# RL6955_IP_SVD register map
Vendor: Realtek
Registers are 32-bit, read-write, reset 0x0 unless marked. A register's access mark holds for its fields unless they carry their own. Offsets are from the block's base; [hi:lo] are bit positions; {n}, {i} and the like mark numbered series; <NAME> marks a mode.

## MGEN_ON
Base 0x40000000
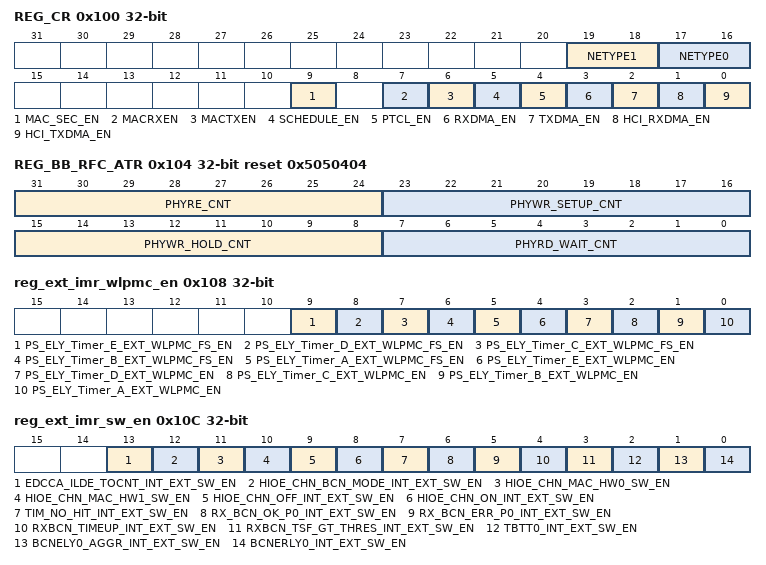
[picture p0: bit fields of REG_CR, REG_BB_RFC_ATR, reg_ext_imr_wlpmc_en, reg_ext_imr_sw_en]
0x100 REG_CR — MAC TOP Function enable
  [19:18] NETYPE1 — Network Type for Port 1 00: No link 01: Link in ad hoc network 10: Link in infrastructure network 11:AP mode Default:00b.
  [17:16] NETYPE0 — Network Type for port 0 00: No link 01: Link in ad hoc network 10: Link in infrastructure network 11:AP mode Default:00b.
  [9] MAC_SEC_EN — Enable MAC security engine When this bit is clear, security engine is reset
  [7] MACRXEN — MAC Receiver Enable. When set to 1, and the receive state machine is idle, the receive machine becomes active. This bit will read back as 1 whenever the receive state machine is active. After initial power-up, software must ensure that the receiver has completely reset before setting this bit. 1: Enable 0: Disable Default: 0b.
  [6] MACTXEN — MAC Transmitter Enable. When set to 1, and the transmit state machine is idle, the transmit state machine becomes active. This bit will read back as 1 whenever the transmit state machine is active. After initial power-up, software must ensure that the transmitter has completely reset before setting this bit. 1: Enable 0: Disable Default: 0b.
  [5] SCHEDULE_EN — Schedule Enable.
  [4] PTCL_EN — protocol Block Function Enable.(FW2HW)
  [3] RXDMA_EN — RXDMA Function Enable
  [2] TXDMA_EN — TXDMA Function Enable
  [1] HCI_RXDMA_EN — HCI to RXDMA Interface Enable
  [0] HCI_TXDMA_EN — HCI to TXDMA Interface Enable
0x104 REG_BB_RFC_ATR reset 0x5050404 — BB/RFC REG Access Time Register
  [31:24] PHYRE_CNT
  [23:16] PHYWR_SETUP_CNT — the timing WDATA stable before WE for host/cpu access BB/RFC REG
  [15:8] PHYWR_HOLD_CNT — the timing WDATA stable after WE for host/cpu access BB/RFC REG
  [7:0] PHYRD_WAIT_CNT — the timing RDATA stable after ADDR for host/cpu access BB/RFC REG
0x108 reg_ext_imr_wlpmc_en
  [9] PS_ELY_Timer_E_EXT_WLPMC_FS_EN, [8] PS_ELY_Timer_D_EXT_WLPMC_FS_EN, [7] PS_ELY_Timer_C_EXT_WLPMC_FS_EN, [6] PS_ELY_Timer_B_EXT_WLPMC_FS_EN, [5] PS_ELY_Timer_A_EXT_WLPMC_FS_EN, [4] PS_ELY_Timer_E_EXT_WLPMC_EN, [3] PS_ELY_Timer_D_EXT_WLPMC_EN, [2] PS_ELY_Timer_C_EXT_WLPMC_EN, [1] PS_ELY_Timer_B_EXT_WLPMC_EN, [0] PS_ELY_Timer_A_EXT_WLPMC_EN
0x10C reg_ext_imr_sw_en
  [13] EDCCA_ILDE_TOCNT_INT_EXT_SW_EN — when edcca is low after tbtt, start timer,when timeout for few times,set this interrupt
  [12] HIOE_CHN_BCN_MODE_INT_EXT_SW_EN — hioe_chn_bcn_mode done interrupt
  [11] HIOE_CHN_MAC_HW0_SW_EN — hioe_chn_mac_hw0 done interrupt
  [10] HIOE_CHN_MAC_HW1_SW_EN — hioe_chn_mac_hw1 done interrupt
  [9] HIOE_CHN_OFF_INT_EXT_SW_EN — hioe_chn_off done interrupt
  [8] HIOE_CHN_ON_INT_EXT_SW_EN — hioe_chn_on done interrupt
  [7] TIM_NO_HIT_INT_EXT_SW_EN — when no my aid or aid is 0(0x16DC[8]) or my bssid is not in tim element(0x16DB[31]),generate this interrupt
  [6] RX_BCN_OK_P0_INT_EXT_SW_EN — When this bit is enable, the interrupt is issued when RX beacon frame occurs in port0.
  [5] RX_BCN_ERR_P0_INT_EXT_SW_EN — When this bit is enable, the interrupt is issued when RX beacon frame with fcs error occurs in port0.
  [4] RXBCN_TIMEUP_INT_EXT_SW_EN — When this bit is enable, the interrupt is issued when RX beacon frame timeout occurs in port0.
  [3] RXBCN_TSF_GT_THRES_INT_EXT_SW_EN — The interrupt is issued when difference of tsft in beacon frame of port0 is greater than threshold
  [2] TBTT0_INT_EXT_SW_EN — the interrupt from the exact TBTT time for P0 MBSSID0.
  [1] BCNELY0_AGGR_INT_EXT_SW_EN — port 0 Beacon early aggregation interrupt
  [0] BCNERLY0_INT_EXT_SW_EN — This interrupt is issued at the time set by DRVERLYINT register before TBTT0_MB0 time.
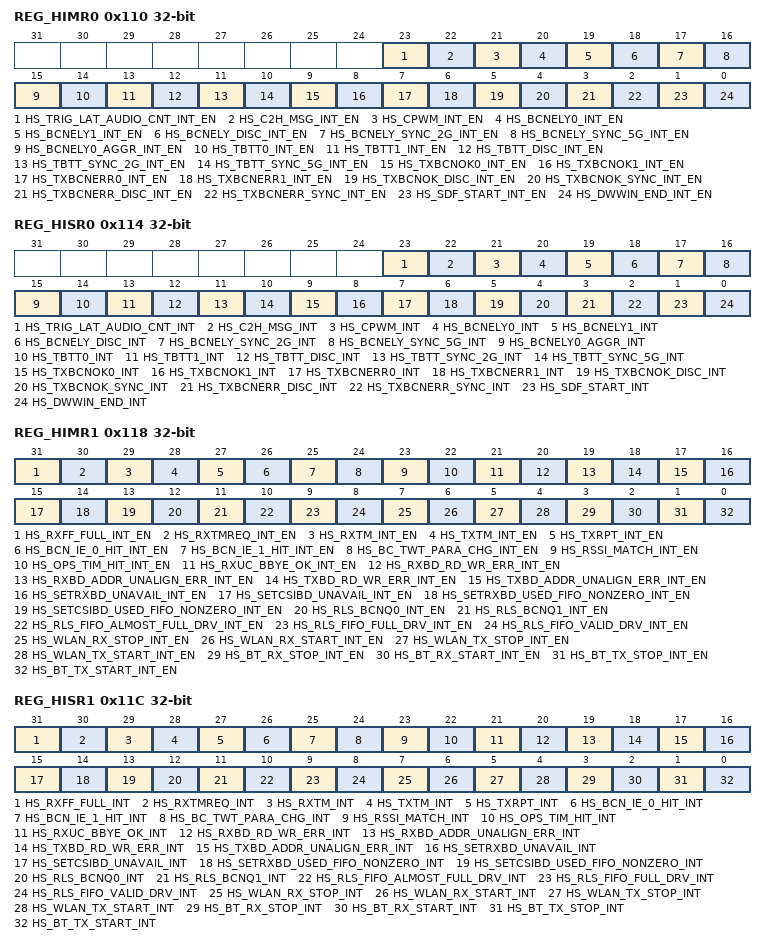
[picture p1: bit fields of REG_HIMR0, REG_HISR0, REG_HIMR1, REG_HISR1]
0x110 REG_HIMR0
  [23] HS_TRIG_LAT_AUDIO_CNT_INT_EN, [22] HS_C2H_MSG_INT_EN, [21] HS_CPWM_INT_EN, [20] HS_BCNELY0_INT_EN, [19] HS_BCNELY1_INT_EN, [18] HS_BCNELY_DISC_INT_EN, [17] HS_BCNELY_SYNC_2G_INT_EN, [16] HS_BCNELY_SYNC_5G_INT_EN, [15] HS_BCNELY0_AGGR_INT_EN, [14] HS_TBTT0_INT_EN, [13] HS_TBTT1_INT_EN, [12] HS_TBTT_DISC_INT_EN, [11] HS_TBTT_SYNC_2G_INT_EN, [10] HS_TBTT_SYNC_5G_INT_EN, [9] HS_TXBCNOK0_INT_EN, [8] HS_TXBCNOK1_INT_EN, [7] HS_TXBCNERR0_INT_EN, [6] HS_TXBCNERR1_INT_EN, [5] HS_TXBCNOK_DISC_INT_EN, [4] HS_TXBCNOK_SYNC_INT_EN, [3] HS_TXBCNERR_DISC_INT_EN, [2] HS_TXBCNERR_SYNC_INT_EN, [1] HS_SDF_START_INT_EN, [0] HS_DWWIN_END_INT_EN
0x114 REG_HISR0 ro
  [23] HS_TRIG_LAT_AUDIO_CNT_INT, [22] HS_C2H_MSG_INT, [21] HS_CPWM_INT, [20] HS_BCNELY0_INT, [19] HS_BCNELY1_INT, [18] HS_BCNELY_DISC_INT, [17] HS_BCNELY_SYNC_2G_INT, [16] HS_BCNELY_SYNC_5G_INT, [15] HS_BCNELY0_AGGR_INT, [14] HS_TBTT0_INT, [13] HS_TBTT1_INT, [12] HS_TBTT_DISC_INT, [11] HS_TBTT_SYNC_2G_INT, [10] HS_TBTT_SYNC_5G_INT, [9] HS_TXBCNOK0_INT, [8] HS_TXBCNOK1_INT, [7] HS_TXBCNERR0_INT, [6] HS_TXBCNERR1_INT, [5] HS_TXBCNOK_DISC_INT, [4] HS_TXBCNOK_SYNC_INT, [3] HS_TXBCNERR_DISC_INT, [2] HS_TXBCNERR_SYNC_INT, [1] HS_SDF_START_INT, [0] HS_DWWIN_END_INT
0x118 REG_HIMR1
  [31] HS_RXFF_FULL_INT_EN, [30] HS_RXTMREQ_INT_EN, [29] HS_RXTM_INT_EN, [28] HS_TXTM_INT_EN, [27] HS_TXRPT_INT_EN, [26] HS_BCN_IE_0_HIT_INT_EN, [25] HS_BCN_IE_1_HIT_INT_EN, [24] HS_BC_TWT_PARA_CHG_INT_EN, [23] HS_RSSI_MATCH_INT_EN, [22] HS_OPS_TIM_HIT_INT_EN, [21] HS_RXUC_BBYE_OK_INT_EN, [20] HS_RXBD_RD_WR_ERR_INT_EN, [19] HS_RXBD_ADDR_UNALIGN_ERR_INT_EN, [18] HS_TXBD_RD_WR_ERR_INT_EN, [17] HS_TXBD_ADDR_UNALIGN_ERR_INT_EN, [16] HS_SETRXBD_UNAVAIL_INT_EN, [15] HS_SETCSIBD_UNAVAIL_INT_EN, [14] HS_SETRXBD_USED_FIFO_NONZERO_INT_EN, [13] HS_SETCSIBD_USED_FIFO_NONZERO_INT_EN, [12] HS_RLS_BCNQ0_INT_EN, [11] HS_RLS_BCNQ1_INT_EN, [10] HS_RLS_FIFO_ALMOST_FULL_DRV_INT_EN, [9] HS_RLS_FIFO_FULL_DRV_INT_EN, [8] HS_RLS_FIFO_VALID_DRV_INT_EN, [7] HS_WLAN_RX_STOP_INT_EN, [6] HS_WLAN_RX_START_INT_EN, [5] HS_WLAN_TX_STOP_INT_EN, [4] HS_WLAN_TX_START_INT_EN, [3] HS_BT_RX_STOP_INT_EN, [2] HS_BT_RX_START_INT_EN, [1] HS_BT_TX_STOP_INT_EN, [0] HS_BT_TX_START_INT_EN
0x11C REG_HISR1 ro
  [31] HS_RXFF_FULL_INT, [30] HS_RXTMREQ_INT, [29] HS_RXTM_INT, [28] HS_TXTM_INT, [27] HS_TXRPT_INT, [26] HS_BCN_IE_0_HIT_INT, [25] HS_BCN_IE_1_HIT_INT, [24] HS_BC_TWT_PARA_CHG_INT, [23] HS_RSSI_MATCH_INT, [22] HS_OPS_TIM_HIT_INT, [21] HS_RXUC_BBYE_OK_INT, [20] HS_RXBD_RD_WR_ERR_INT, [19] HS_RXBD_ADDR_UNALIGN_ERR_INT, [18] HS_TXBD_RD_WR_ERR_INT, [17] HS_TXBD_ADDR_UNALIGN_ERR_INT, [16] HS_SETRXBD_UNAVAIL_INT, [15] HS_SETCSIBD_UNAVAIL_INT, [14] HS_SETRXBD_USED_FIFO_NONZERO_INT, [13] HS_SETCSIBD_USED_FIFO_NONZERO_INT, [12] HS_RLS_BCNQ0_INT, [11] HS_RLS_BCNQ1_INT, [10] HS_RLS_FIFO_ALMOST_FULL_DRV_INT, [9] HS_RLS_FIFO_FULL_DRV_INT, [8] HS_RLS_FIFO_VALID_DRV_INT, [7] HS_WLAN_RX_STOP_INT, [6] HS_WLAN_RX_START_INT, [5] HS_WLAN_TX_STOP_INT, [4] HS_WLAN_TX_START_INT, [3] HS_BT_RX_STOP_INT, [2] HS_BT_RX_START_INT, [1] HS_BT_TX_STOP_INT, [0] HS_BT_TX_START_INT
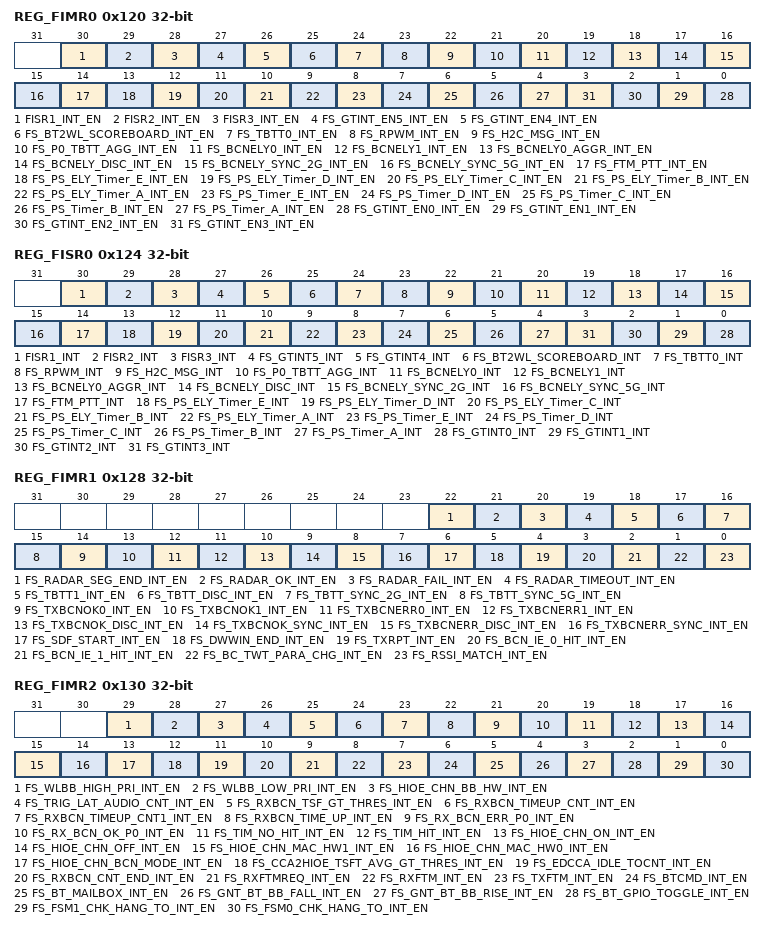
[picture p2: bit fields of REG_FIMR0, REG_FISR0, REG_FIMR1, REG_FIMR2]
0x120 REG_FIMR0
  [30] FISR1_INT_EN — FISR1 Indicator
  [29] FISR2_INT_EN — FISR2 Indicator
  [28] FISR3_INT_EN — FISR3 Indicator
  [27] FS_GTINT_EN5_INT_EN — General Timer[5] interrupt
  [26] FS_GTINT_EN4_INT_EN — General Timer[4] interrupt
  [25] FS_BT2WL_SCOREBOARD_INT_EN
  [24] FS_TBTT0_INT_EN
  [23] FS_RPWM_INT_EN
  [22] FS_H2C_MSG_INT_EN
  [21] FS_P0_TBTT_AGG_INT_EN — the interrupt from the multiplt TBTT times for P0.
  [20] FS_BCNELY0_INT_EN
  [19] FS_BCNELY1_INT_EN
  [18] FS_BCNELY0_AGGR_INT_EN
  [17] FS_BCNELY_DISC_INT_EN
  [16] FS_BCNELY_SYNC_2G_INT_EN
  [15] FS_BCNELY_SYNC_5G_INT_EN
  [14] FS_FTM_PTT_INT_EN
  [13] FS_PS_ELY_Timer_E_INT_EN
  [12] FS_PS_ELY_Timer_D_INT_EN
  [11] FS_PS_ELY_Timer_C_INT_EN
  [10] FS_PS_ELY_Timer_B_INT_EN
  [9] FS_PS_ELY_Timer_A_INT_EN
  [8] FS_PS_Timer_E_INT_EN
  [7] FS_PS_Timer_D_INT_EN
  [6] FS_PS_Timer_C_INT_EN
  [5] FS_PS_Timer_B_INT_EN
  [4] FS_PS_Timer_A_INT_EN
  [n] FS_GTINT_EN{n}_INT_EN (n=0..3) — General Timer[{n}] interrupt
0x124 REG_FISR0 ro
  [30] FISR1_INT — FISR1 Indicator
  [29] FISR2_INT — FISR2 Indicator
  [28] FISR3_INT — FISR3 Indicator
  [27] FS_GTINT5_INT — General Timer[5] interrupt
  [26] FS_GTINT4_INT — General Timer[4] interrupt
  [25] FS_BT2WL_SCOREBOARD_INT
  [24] FS_TBTT0_INT
  [23] FS_RPWM_INT
  [22] FS_H2C_MSG_INT
  [21] FS_P0_TBTT_AGG_INT — the interrupt from the multiplt TBTT times for P0.
  [20] FS_BCNELY0_INT
  [19] FS_BCNELY1_INT
  [18] FS_BCNELY0_AGGR_INT
  [17] FS_BCNELY_DISC_INT
  [16] FS_BCNELY_SYNC_2G_INT
  [15] FS_BCNELY_SYNC_5G_INT
  [14] FS_FTM_PTT_INT
  [13] FS_PS_ELY_Timer_E_INT
  [12] FS_PS_ELY_Timer_D_INT
  [11] FS_PS_ELY_Timer_C_INT
  [10] FS_PS_ELY_Timer_B_INT
  [9] FS_PS_ELY_Timer_A_INT
  [8] FS_PS_Timer_E_INT
  [7] FS_PS_Timer_D_INT
  [6] FS_PS_Timer_C_INT
  [5] FS_PS_Timer_B_INT
  [4] FS_PS_Timer_A_INT
  [n] FS_GTINT{n}_INT (n=0..3) — General Timer[{n}] interrupt
0x128 REG_FIMR1
  [22] FS_RADAR_SEG_END_INT_EN, [21] FS_RADAR_OK_INT_EN, [20] FS_RADAR_FAIL_INT_EN, [19] FS_RADAR_TIMEOUT_INT_EN, [18] FS_TBTT1_INT_EN, [17] FS_TBTT_DISC_INT_EN, [16] FS_TBTT_SYNC_2G_INT_EN, [15] FS_TBTT_SYNC_5G_INT_EN, [14] FS_TXBCNOK0_INT_EN, [13] FS_TXBCNOK1_INT_EN, [12] FS_TXBCNERR0_INT_EN, [11] FS_TXBCNERR1_INT_EN, [10] FS_TXBCNOK_DISC_INT_EN, [9] FS_TXBCNOK_SYNC_INT_EN, [8] FS_TXBCNERR_DISC_INT_EN, [7] FS_TXBCNERR_SYNC_INT_EN, [6] FS_SDF_START_INT_EN, [5] FS_DWWIN_END_INT_EN, [4] FS_TXRPT_INT_EN, [3] FS_BCN_IE_0_HIT_INT_EN, [2] FS_BCN_IE_1_HIT_INT_EN, [1] FS_BC_TWT_PARA_CHG_INT_EN, [0] FS_RSSI_MATCH_INT_EN
0x130 REG_FIMR2
  [29] FS_WLBB_HIGH_PRI_INT_EN, [28] FS_WLBB_LOW_PRI_INT_EN, [27] FS_HIOE_CHN_BB_HW_INT_EN, [26] FS_TRIG_LAT_AUDIO_CNT_INT_EN, [25] FS_RXBCN_TSF_GT_THRES_INT_EN, [24] FS_RXBCN_TIMEUP_CNT_INT_EN, [23] FS_RXBCN_TIMEUP_CNT1_INT_EN, [22] FS_RXBCN_TIME_UP_INT_EN, [21] FS_RX_BCN_ERR_P0_INT_EN, [20] FS_RX_BCN_OK_P0_INT_EN, [19] FS_TIM_NO_HIT_INT_EN, [18] FS_TIM_HIT_INT_EN, [17] FS_HIOE_CHN_ON_INT_EN, [16] FS_HIOE_CHN_OFF_INT_EN, [15] FS_HIOE_CHN_MAC_HW1_INT_EN, [14] FS_HIOE_CHN_MAC_HW0_INT_EN, [13] FS_HIOE_CHN_BCN_MODE_INT_EN, [12] FS_CCA2HIOE_TSFT_AVG_GT_THRES_INT_EN, [11] FS_EDCCA_IDLE_TOCNT_INT_EN, [10] FS_RXBCN_CNT_END_INT_EN, [9] FS_RXFTMREQ_INT_EN, [8] FS_RXFTM_INT_EN, [7] FS_TXFTM_INT_EN, [6] FS_BTCMD_INT_EN, [5] FS_BT_MAILBOX_INT_EN, [4] FS_GNT_BT_BB_FALL_INT_EN, [3] FS_GNT_BT_BB_RISE_INT_EN, [2] FS_BT_GPIO_TOGGLE_INT_EN, [1] FS_FSM1_CHK_HANG_TO_INT_EN, [0] FS_FSM0_CHK_HANG_TO_INT_EN
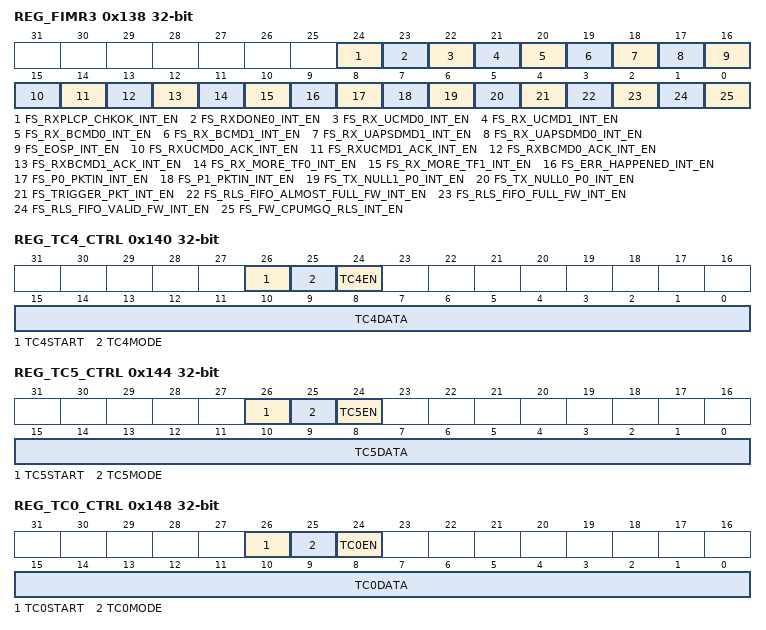
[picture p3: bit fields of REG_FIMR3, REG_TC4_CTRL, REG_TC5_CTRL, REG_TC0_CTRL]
0x138 REG_FIMR3
  [24] FS_RXPLCP_CHKOK_INT_EN — RXPCLP check ok interrupt
  [23] FS_RXDONE0_INT_EN — Rx Packet 0 done interrupt (for WOL release packet)
  [22] FS_RX_UCMD0_INT_EN — The interrupt is issued while receiving unicast data frame with More Data=0
  [21] FS_RX_UCMD1_INT_EN — The interrupt is issued while receiving unicast data frame with More Data=1
  [20] FS_RX_BCMD0_INT_EN — The interrupt is issued while receiving broadcast data frame with More Data=0
  [19] FS_RX_BCMD1_INT_EN — The interrupt is issued while receiving broadcast data frame with More Data=1
  [18] FS_RX_UAPSDMD1_INT_EN — Setting this bit indicates Rx pkt is matched with one of below: 1.) QoS Unicast data frame with MD=1, UAPSD=0 2.) NonQoS Unicast data frame with MD=1
  [17] FS_RX_UAPSDMD0_INT_EN — Setting this bit indicates Rx pkt is matched with one of below: 1.) QoS Unicast data frame with MD=0, UAPSD=0 2.) NonQoS Unicast data frame with MD=0
  [16] FS_EOSP_INT_EN — EOSP_INT interrupt mask
  [15] FS_RXUCMD0_ACK_INT_EN
  [14] FS_RXUCMD1_ACK_INT_EN
  [13] FS_RXBCMD0_ACK_INT_EN
  [12] FS_RXBCMD1_ACK_INT_EN
  [11] FS_RX_MORE_TF0_INT_EN
  [10] FS_RX_MORE_TF1_INT_EN
  [9] FS_ERR_HAPPENED_INT_EN — FWHW/ WMAC error status interrupt(0x4E2[15:0], 0x6B8[31:0]). WMAC error state will be recovered by HW, the others won't.
  [8] FS_P0_PKTIN_INT_EN — port 0 packet assign to queue interrupt
  [7] FS_P1_PKTIN_INT_EN — port 1 packet assign to queue interrupt
  [6] FS_TX_NULL1_P0_INT_EN — TX null 1 packet done interrupt
  [5] FS_TX_NULL0_P0_INT_EN — TX null 0 packet done interrupt
  [4] FS_TRIGGER_PKT_INT_EN — tx TRIGGER_PKT interrupt
  [3] FS_RLS_FIFO_ALMOST_FULL_FW_INT_EN
  [2] FS_RLS_FIFO_FULL_FW_INT_EN
  [1] FS_RLS_FIFO_VALID_FW_INT_EN
  [0] FS_FW_CPUMGQ_RLS_INT_EN
0x140 REG_TC4_CTRL access per field — Counter 4 CONTROL
  [26] TC4START wo — When write "1" to this bit, Counter 0 starts counting down. This is a one-bit pulse.
  [25] TC4MODE rw — Timer/Counter 4 mode 0=counter mode 1=timer mode
  [24] TC4EN rw — Timer/Counter 4 enable
  [15:0] TC4DATA rw — Timer/Counter 4 data register. It specifies the time-out duration.
0x144 REG_TC5_CTRL access per field — Counter 5 CONTROL
  [26] TC5START wo — When write "1" to this bit, Counter 0 starts counting down. This is a one-bit pulse.
  [25] TC5MODE rw — Timer/Counter 5 mode 0=counter mode 1=timer mode
  [24] TC5EN rw — Timer/Counter 5 enable
  [15:0] TC5DATA rw — Timer/Counter 5 data register. It specifies the time-out duration.
0x148 REG_TC0_CTRL access per field — Counter 0 CONTROL
  [26] TC0START wo — When write "1" to this bit, Counter 0 starts counting down. This is a one-bit pulse.
  [25] TC0MODE rw — Timer/Counter 0 mode 0=counter mode 1=timer mode
  [24] TC0EN rw — Timer/Counter 0 enable
  [15:0] TC0DATA rw — Timer/Counter 0 data register. It specifies the time-out duration.
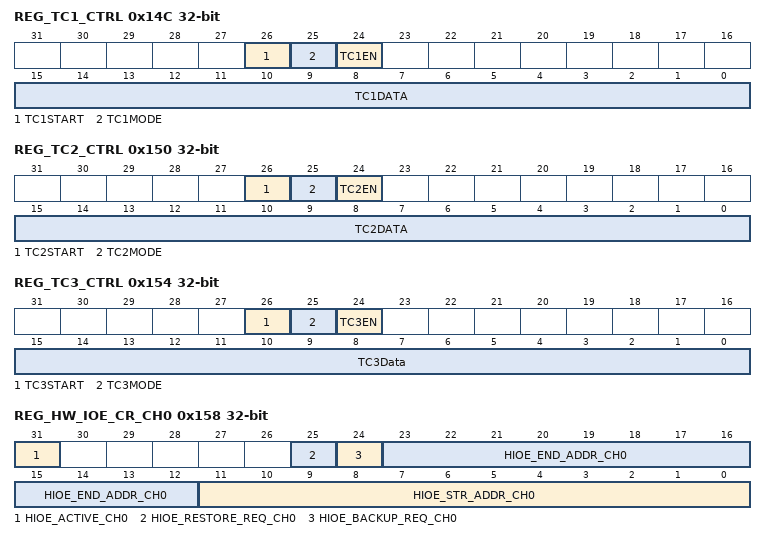
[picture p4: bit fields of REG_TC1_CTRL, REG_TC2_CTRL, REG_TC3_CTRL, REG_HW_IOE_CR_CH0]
0x14C REG_TC1_CTRL access per field — Counter 1 data
  [26] TC1START wo — When write "1" to this bit, Counter 1 starts counting down. This is a one-bit pulse.
  [25] TC1MODE rw — Timer/Counter 1 mode 0=counter mode 1=timer mode
  [24] TC1EN rw — Timer/Counter 1 enable
  [15:0] TC1DATA rw — Timer/Counter 1 data register. It specifies the time-out duration.
0x150 REG_TC2_CTRL access per field — Counter 2 data
  [26] TC2START wo — When write "1" to this bit, Counter 2 starts counting down. This is a one-bit pulse.
  [25] TC2MODE rw — Timer/Counter 2 mode 0=counter mode 1=timer mode
  [24] TC2EN rw — Timer/Counter 2 enable
  [15:0] TC2DATA rw — Timer/Counter 2 data register. It specifies the time-out duration.
0x154 REG_TC3_CTRL access per field — Counter 3 data
  [26] TC3START wo — When write "1" to this bit, Counter 3 starts counting down. This is a one-bit pulse.
  [25] TC3MODE rw — Timer/Counter 3 mode 0=counter mode 1=timer mode
  [24] TC3EN rw — Timer/Counter 3 enable
  [15:0] TC3Data rw — Timer/Counter 3 data register. It specifies the time-out duration.
0x158 REG_HW_IOE_CR_CH0 access per field
  [31] HIOE_ACTIVE_CH0 ro — indicate HIOE engine is active
  [25] HIOE_RESTORE_REQ_CH0 rw — WLOFF REG restore request, clear by hw
  [24] HIOE_BACKUP_REQ_CH0 rw — WLOFF REG backup request, clear by hw
  [23:12] HIOE_END_ADDR_CH0 rw — HIOE command end address in txpktbuffer, unit:8byte
  [11:0] HIOE_STR_ADDR_CH0 rw — HIOE command start address in txpktbuffer, unit:8byte
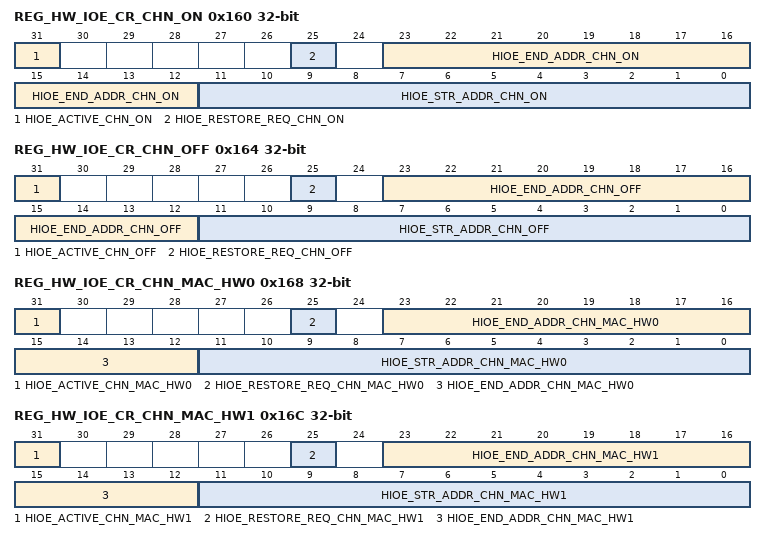
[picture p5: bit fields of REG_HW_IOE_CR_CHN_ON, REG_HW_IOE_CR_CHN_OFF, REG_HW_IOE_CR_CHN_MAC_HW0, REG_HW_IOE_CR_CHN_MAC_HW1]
0x160 REG_HW_IOE_CR_CHN_ON access per field — HW IO Engine Configure Register_CHN_ON
  [31] HIOE_ACTIVE_CHN_ON ro — indicate HIOE engine is active, used for wlan power on flow
  [25] HIOE_RESTORE_REQ_CHN_ON ro — WLOFF REG restore request, clear by hw
  [23:12] HIOE_END_ADDR_CHN_ON rw — HIOE command end address in txpktbuffer, unit:8byte
  [11:0] HIOE_STR_ADDR_CHN_ON rw — HIOE command start address in txpktbuffer, unit:8byte
0x164 REG_HW_IOE_CR_CHN_OFF access per field — HW IO Engine Configure Register_CHN_OFF
  [31] HIOE_ACTIVE_CHN_OFF ro — indicate HIOE engine is active, used for wlan power off flow
  [25] HIOE_RESTORE_REQ_CHN_OFF ro — WLOFF REG restore request, clear by hw
  [23:12] HIOE_END_ADDR_CHN_OFF rw — HIOE command end address in txpktbuffer, unit:8byte
  [11:0] HIOE_STR_ADDR_CHN_OFF rw — HIOE command start address in txpktbuffer, unit:8byte
0x168 REG_HW_IOE_CR_CHN_MAC_HW0 access per field
  [31] HIOE_ACTIVE_CHN_MAC_HW0 ro — indicate HIOE CHN_MAC_HW0 is active
  [25] HIOE_RESTORE_REQ_CHN_MAC_HW0 ro — hw hang trig hioe reset wmac request, clear by hw
  [23:12] HIOE_END_ADDR_CHN_MAC_HW0 rw — HIOE command end address in txpktbuffer, unit:8byte
  [11:0] HIOE_STR_ADDR_CHN_MAC_HW0 rw — HIOE command start address in txpktbuffer, unit:8byte
0x16C REG_HW_IOE_CR_CHN_MAC_HW1 access per field
  [31] HIOE_ACTIVE_CHN_MAC_HW1 ro — indicate HIOE CHN_MAC_HW1 is active
  [25] HIOE_RESTORE_REQ_CHN_MAC_HW1 ro — hw hang trig hioe reset wmac request, clear by hw
  [23:12] HIOE_END_ADDR_CHN_MAC_HW1 rw — HIOE command end address in txpktbuffer, unit:8byte
  [11:0] HIOE_STR_ADDR_CHN_MAC_HW1 rw — HIOE command start address in txpktbuffer, unit:8byte
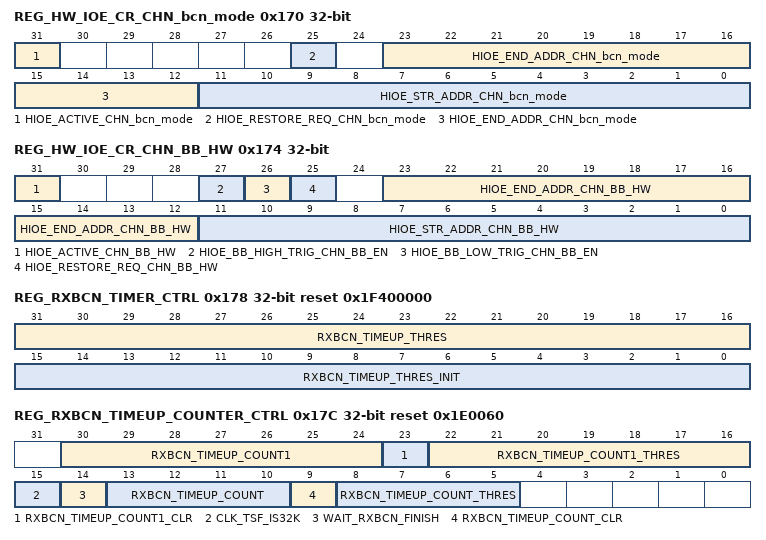
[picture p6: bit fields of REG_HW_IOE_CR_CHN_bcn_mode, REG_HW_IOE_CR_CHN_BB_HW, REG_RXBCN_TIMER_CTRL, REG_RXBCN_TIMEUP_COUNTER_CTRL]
0x170 REG_HW_IOE_CR_CHN_bcn_mode access per field
  [31] HIOE_ACTIVE_CHN_bcn_mode ro — indicate HIOE CHN_bcn_mode is active
  [25] HIOE_RESTORE_REQ_CHN_bcn_mode ro — BB/RF enable OFDM mode request, clear by hw
  [23:12] HIOE_END_ADDR_CHN_bcn_mode rw — HIOE command end address in txpktbuffer, unit:8byte
  [11:0] HIOE_STR_ADDR_CHN_bcn_mode rw — HIOE command start address in txpktbuffer, unit:8byte
0x174 REG_HW_IOE_CR_CHN_BB_HW access per field — HW IO Engine Configure Register_CHN_BB_HW
  [31] HIOE_ACTIVE_CHN_BB_HW ro — indicate HIOE engine is active
  [27] HIOE_BB_HIGH_TRIG_CHN_BB_EN rw — enable bb high pri int to to trig hioe to do bb reset when break happened
  [26] HIOE_BB_LOW_TRIG_CHN_BB_EN rw — enable bb low pri int to to trig hioe to do bb reset when break happened
  [25] HIOE_RESTORE_REQ_CHN_BB_HW ro — WLOFF REG restore request, clear by hw
  [23:12] HIOE_END_ADDR_CHN_BB_HW rw — HIOE command end address in txpktbuffer, unit:8byte
  [11:0] HIOE_STR_ADDR_CHN_BB_HW rw — HIOE command start address in txpktbuffer, unit:8byte
0x178 REG_RXBCN_TIMER_CTRL access per field reset 0x1F400000
  [31:16] RXBCN_TIMEUP_THRES rw — threshold for rxbcn timeout,UNIT:us default:8ms
  [15:0] RXBCN_TIMEUP_THRES_INIT ro — HW auto update threshold for rxbcn timeout,UNIT:us
0x17C REG_RXBCN_TIMEUP_COUNTER_CTRL access per field reset 0x1E0060
  [30:24] RXBCN_TIMEUP_COUNT1 ro — rxbcn timeup counter1
  [23] RXBCN_TIMEUP_COUNT1_CLR wo — clear rxbcn timeup counter1
  [22:16] RXBCN_TIMEUP_COUNT1_THRES rw — threshold for rxbcn timeup counter,when 0x17C[30:24] equals to this value,generate interrupt
  [15] CLK_TSF_IS32K ro — Which Clock is Used by TSF Clock 1: 32K Clock 0: MAC Clock
  [14] WAIT_RXBCN_FINISH rw — when rxbcn frame,turn off rf or generate interrupt ablout rxbcn after beacon fcs is parsered
  [13:10] RXBCN_TIMEUP_COUNT ro — rxbcn timeup counter
  [9] RXBCN_TIMEUP_COUNT_CLR wo — clear rxbcn timeup counter
  [8:5] RXBCN_TIMEUP_COUNT_THRES rw — threshold for rxbcn timeout counter,when 0x17C[13:10] equals to this value,generate interrupt
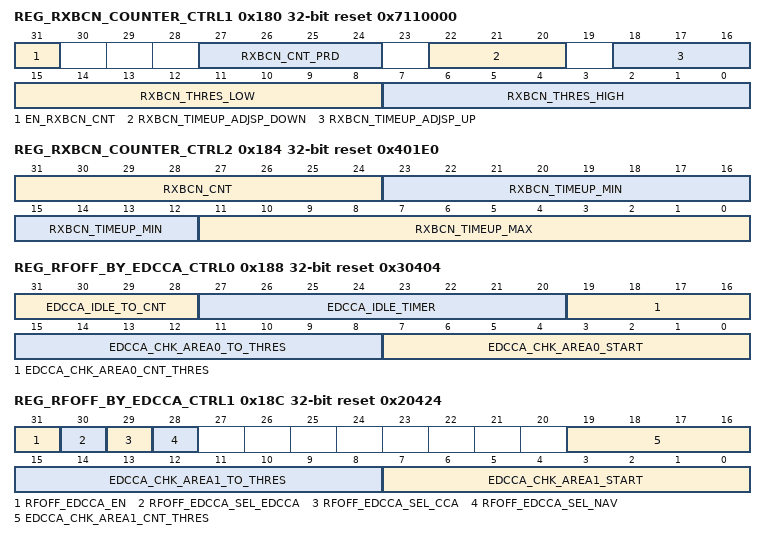
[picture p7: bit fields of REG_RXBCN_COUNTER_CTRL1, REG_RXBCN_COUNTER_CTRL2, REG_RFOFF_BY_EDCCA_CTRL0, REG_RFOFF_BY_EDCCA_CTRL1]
0x180 REG_RXBCN_COUNTER_CTRL1 reset 0x7110000
  [31] EN_RXBCN_CNT — 1: statistic the number of RXBCN in specified period
  [27:24] RXBCN_CNT_PRD — 2^(RXBCN_CNT_PRD), default is 128 times
  [22:20] RXBCN_TIMEUP_ADJSP_DOWN — the adjust step of the rxbcn timeup period adjustment when decrease the period. UNIT: (2^RXBCN_TIMEUP_ADJSP_DOWN)*32US
  [18:16] RXBCN_TIMEUP_ADJSP_UP — the adjust step of the rxbcn timeup period adjustment when increase the period. UNIT: (2^RXBCN_TIMEUP_ADJSP_UP)*32US
  [15:8] RXBCN_THRES_LOW — lower limit of rxbcn. If the RXBCN.COUNTER < THRES_LOW, RXBCN timeup period + (2^RXBCN_TIMEUP_ADJSP_UP)*32US
  [7:0] RXBCN_THRES_HIGH — upper limit of rxbcn. If the RXBCN.COUNTER > THRES_HIGH, RXBCN timeup period - (2^RXBCN_TIMEUP_ADJSP_DOWN)*32US
0x184 REG_RXBCN_COUNTER_CTRL2 access per field reset 0x401E0
  [31:24] RXBCN_CNT ro — statistic the times of RXBCN in RXBCN_CNT_PRD
  [23:12] RXBCN_TIMEUP_MIN rw — lower limit of bcn_timeup. If the bcn_timeup less than RXBCN_TIMRUP_MIN, use the RXBCN_TIMRUP_MIN as bcn_timeup. UNIT: 32US. Default is 2ms
  [11:0] RXBCN_TIMEUP_MAX rw — upper limit of bcn_timeup. If the bcn_timeup greater than RXBCN_TIMRUP_MAX, use the RXBCN_TIMRUP_MAX as bcn_timeup. UNIT: 32US. Default is 15ms
0x188 REG_RFOFF_BY_EDCCA_CTRL0 access per field reset 0x30404
  [31:28] EDCCA_IDLE_TO_CNT ro — indicate how many times edcca idle timeout happens
  [27:20] EDCCA_IDLE_TIMER ro — edcca idle timeout timer,unit:4us
  [19:16] EDCCA_CHK_AREA0_CNT_THRES rw — EDCCA_IDLE timeout counter treshold in area0,when timeout counter greater than threshold, generate interrupt
  [15:8] EDCCA_CHK_AREA0_TO_THRES rw — EDCCA_IDLE timeout threshold in area0,unit:4us,default:16us
  [7:0] EDCCA_CHK_AREA0_START rw — EDCCA_IDLE_area0 end time,start form TBTT,unit:256us,default:1.024ms
0x18C REG_RFOFF_BY_EDCCA_CTRL1 reset 0x20424
  [31] RFOFF_EDCCA_EN — enable function of rf off by edcca idle timeout
  [30] RFOFF_EDCCA_SEL_EDCCA — 1:sel edcca as instruction
  [29] RFOFF_EDCCA_SEL_CCA — 1:sel cca as instruction
  [28] RFOFF_EDCCA_SEL_NAV — 1:sel nav as instruction
  [19:16] EDCCA_CHK_AREA1_CNT_THRES — EDCCA_IDLE timeout counter treshold in area1,when timeout counter greater than threshold, generate interrupt
  [15:8] EDCCA_CHK_AREA1_TO_THRES — EDCCA_IDLE timeout threshold in area1,unit:4us,default:16us
  [7:0] EDCCA_CHK_AREA1_START — EDCCA_IDLE_area1 start time,start form TBTT,unit:256us,default:9.216ms
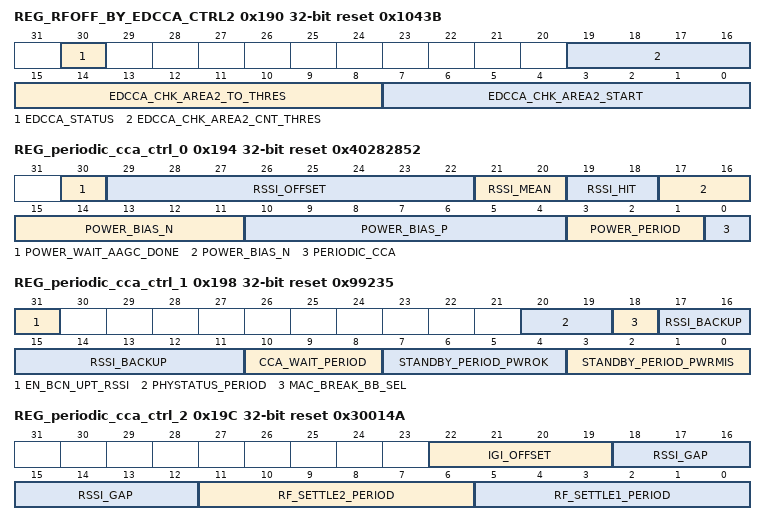
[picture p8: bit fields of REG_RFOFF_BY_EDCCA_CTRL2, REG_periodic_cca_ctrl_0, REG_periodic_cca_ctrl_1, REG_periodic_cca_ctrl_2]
0x190 REG_RFOFF_BY_EDCCA_CTRL2 access per field reset 0x1043B
  [30] EDCCA_STATUS ro — indicate edcca or edcca|cca status of channel
  [19:16] EDCCA_CHK_AREA2_CNT_THRES rw — EDCCA_IDLE timeout counter treshold in AREA2,when timeout counter greater than threshold, generate interrupt
  [15:8] EDCCA_CHK_AREA2_TO_THRES rw — EDCCA_IDLE timeout threshold in AREA2,unit:4us,default:16us
  [7:0] EDCCA_CHK_AREA2_START rw — EDCCA_IDLE_AREA2 start time,start form TBTT,unit:256us,default:15.104ms
0x194 REG_periodic_cca_ctrl_0 reset 0x40282852
  [30] POWER_WAIT_AAGC_DONE — set1:when cca rsie up before power detect done,wait aagc_done to reenter power detect
  [29:22] RSSI_OFFSET — S(8,0), offset for beacon rssi(signed)
  [21:20] RSSI_MEAN — RSSI LATCH mean by 1cycle/2cycle/4 cycle/8cycle
  [19:18] RSSI_HIT — RSSI hit with 1cycle/2cycle/4cycle/8cylce
  [17:11] POWER_BIAS_N — Power calculated by aagc model compared with r_rssi_backup minus r_power_bias_n(unsigned)
  [10:4] POWER_BIAS_P — Power calculated by aagc model compared with r_rssi_backup plus r_power_bias_p(unsigned)
  [3:1] POWER_PERIOD — Period time for calculate power 0:0.8us /1:1.6us /2:2.4us 3:3.2us /4:4.0us /5:4.8us 6:5.6us /7:6.4us
  [0] PERIODIC_CCA — Enable or disable periodic cca function when rxbcn
0x198 REG_periodic_cca_ctrl_1 reset 0x99235
  [31] EN_BCN_UPT_RSSI — update rssi_backup when rx bcn with address match
  [20:19] PHYSTATUS_PERIOD — Period time for cca end to data on end and phystatus upload and RF settling 0:1us /1:2us /2:3us/ 3:4us
  [18] MAC_BREAK_BB_SEL — 0: use BBRST=0 (function disable) to break bb 1:not break bb
  [17:11] RSSI_BACKUP — Backup rssi (unsigned)
  [10:8] CCA_WAIT_PERIOD — Wait time for CCK CCA 0:5us /1:10us /2:15us 3:20us /4:25us /5:30us 6:35us /7:40us
  [7:4] STANDBY_PERIOD_PWROK — Period time for RF standby if power is match 0:30us/1:35us /1:40us/ 2:45us/ 3:50us 4:55us /5:60us.. 14:105us/ 15:110us
  [3:0] STANDBY_PERIOD_PWRMIS — Period time for RF standby if power is mismatch 0:30us/1:35us /1:40us/ 2:45us/ 3:50us 4:55us /5:60us.. 14:105us/ 15:110us
0x19C REG_periodic_cca_ctrl_2 reset 0x30014A
  [22:19] IGI_OFFSET — S(4,0), offset for beacon rssi(unsigned)
  [18:12] RSSI_GAP — if the difference of average rssi between state of power monitor and state of wait cca is too large(>=r_rssi_gap),the cca will be thought as false alarm
  [11:6] RF_SETTLE2_PERIOD — settling time for RF if BB & RF is already enabled, 0:0us, 1:0.2us, 2:0.4us and so on
  [5:0] RF_SETTLE1_PERIOD — settling time for RF if BB & RF is enabled form standby mode, 0:0us, 1:0.2us, 2:0.4us and so on
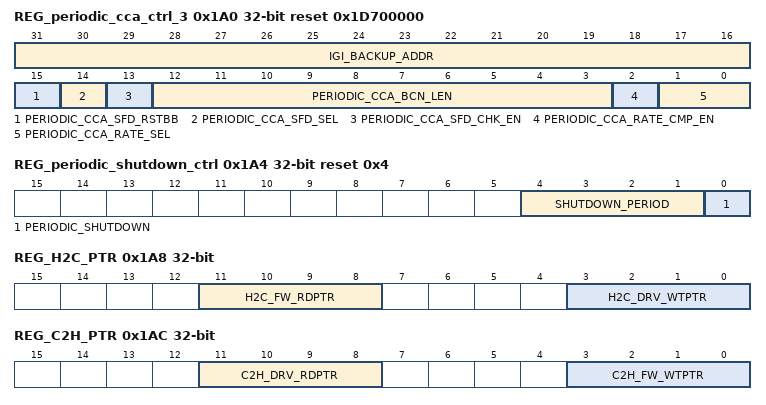
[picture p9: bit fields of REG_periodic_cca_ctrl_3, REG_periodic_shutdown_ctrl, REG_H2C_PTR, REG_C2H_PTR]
0x1A0 REG_periodic_cca_ctrl_3 reset 0x1D700000
  [31:16] IGI_BACKUP_ADDR — Reg address for igi information (for amebad,igi reg is set in BB reg 0x1d70)
  [15] PERIODIC_CCA_SFD_RSTBB — 1:mac check sfd fail will rstbb 0:mac check sfd fail will not rstbb
  [14] PERIODIC_CCA_SFD_SEL — 0:check sfd of long plcp of received beacon 1:check sfd of short plcp of received beacon
  [13] PERIODIC_CCA_SFD_CHK_EN — Enable check long plcp preamble or short preamble
  [12:3] PERIODIC_CCA_BCN_LEN — Supposed Length of beacon, unit:byte If set to 0, not check length of beacon
  [2] PERIODIC_CCA_RATE_CMP_EN — 1:enable rate compare when periodic cca 0:disable rate compare when periodic cca
  [1:0] PERIODIC_CCA_RATE_SEL — If rate mismatch, break bb 0:CCK 1M; 1:CCK 2M; 2:CCK 5.5M; 3:CCK11M
0x1A4 REG_periodic_shutdown_ctrl reset 0x4
  [4:1] SHUTDOWN_PERIOD — Period time for RF shutdown if power is match 0:60us /1:80us/ 2:100us/ 3:120us 4:140us /5:160us.. 14:340us/ 15:360us
  [0] PERIODIC_SHUTDOWN — Enable or disable periodic shutdown BB&RF
0x1A8 REG_H2C_PTR — Host mailbox Read/write pointer
  [11:8] H2C_FW_RDPTR — When FW is noticed by the interrupt generated by 0x1CC[15:0],it will read this read pointer first then read H2C ram unit read pointer equals to write pointer,and update this read pointer in the end
  [3:0] H2C_DRV_WTPTR — Host Write This Byte will generate interrupt to FW,and fw will read ram for h2c message according to this pointer
0x1AC REG_C2H_PTR — fw mailbox Read/write pointer
  [11:8] C2H_DRV_RDPTR — When HOST is noticed by the interrupt generated by 0x1CC[15:0],it will read this read pointer first then read C2H ram unit read pointer equals to write pointer,and update this read pointer in the end
  [3:0] C2H_FW_WTPTR — FW Write This Byte will generate interrupt to HOST,and HOST will read ram for h2c message according to this pointer
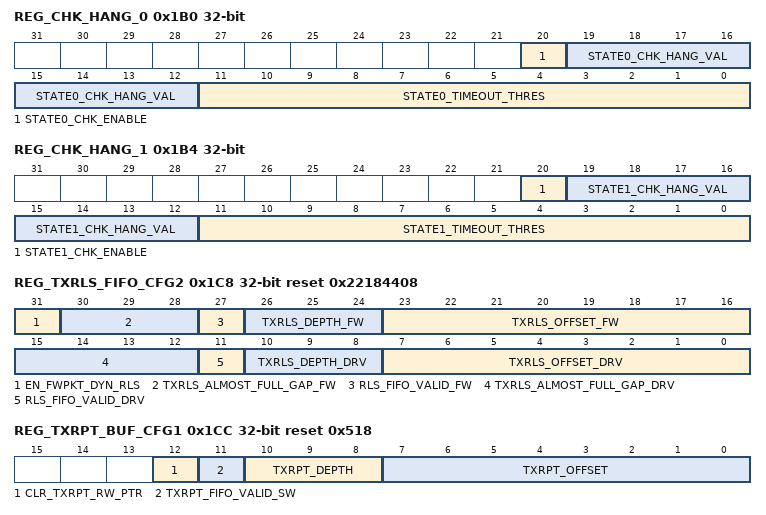
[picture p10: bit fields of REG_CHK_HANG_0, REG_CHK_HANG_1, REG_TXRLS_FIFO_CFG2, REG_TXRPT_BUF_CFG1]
0x1B0 REG_CHK_HANG_0
  [20] STATE0_CHK_ENABLE — function enable of check hang of state_0
  [19:12] STATE0_CHK_HANG_VAL — when r_state0_chk_enable is set, if state_0 is the value is equal to r_state0_chk_hang, starts state0_timeout_timer
  [11:0] STATE0_TIMEOUT_THRES — timeout threshold of state0_timeout_timer, unit:16us
0x1B4 REG_CHK_HANG_1
  [20] STATE1_CHK_ENABLE — function enable of check hang of state_1
  [19:12] STATE1_CHK_HANG_VAL — when r_state1_chk_enable is set, if state_1 is the value is equal to r_state1_chk_hang, starts state1_timeout_timer
  [11:0] STATE1_TIMEOUT_THRES — timeout threshold of state0_timeout_timer, unit:16us
0x1C8 REG_TXRLS_FIFO_CFG2 access per field reset 0x22184408
  [31] EN_FWPKT_DYN_RLS rw — 1: enable fw packet dynamic release
  [30:28] TXRLS_ALMOST_FULL_GAP_FW rw — TXRLS fifo almost full threshold. Gen interrupt when available TXRLS FIFO entries smaller than the reg. for fw packet
  [27] RLS_FIFO_VALID_FW ro — 1: Release fifo is unempty,fw can read release fifo
  [26:24] TXRLS_DEPTH_FW rw — 2^N, N max is 6. default is 4
  [23:16] TXRLS_OFFSET_FW rw — start address of TXRLS FIFO, for fw packet dynamic release FW packet default is static release, if EN_FWPKT_DYN_RLS = 1, need to change all FIFO REG offset
  [15:12] TXRLS_ALMOST_FULL_GAP_DRV rw — TXRLS fifo almost full threshold. Gen interrupt when available TXRLS FIFO entries smaller than the reg. for driver packet
  [11] RLS_FIFO_VALID_DRV ro — 1: Release fifo is unempty,driver can read release fifo
  [10:8] TXRLS_DEPTH_DRV rw — 2^N, N max is 6. default is 16
  [7:0] TXRLS_OFFSET_DRV rw — start address of TXRLS FIFO, for driver packet
0x1CC REG_TXRPT_BUF_CFG1 access per field reset 0x518
  [12] CLR_TXRPT_RW_PTR rw — 1: clear r/w ptr of txrpt fifo
  [11] TXRPT_FIFO_VALID_SW ro — 1: Release fifo is unempty,driver can read release fifo
  [10:8] TXRPT_DEPTH rw — 2^N, N max is 6. default is 32
  [7:0] TXRPT_OFFSET rw — start address of TXRPT BUF
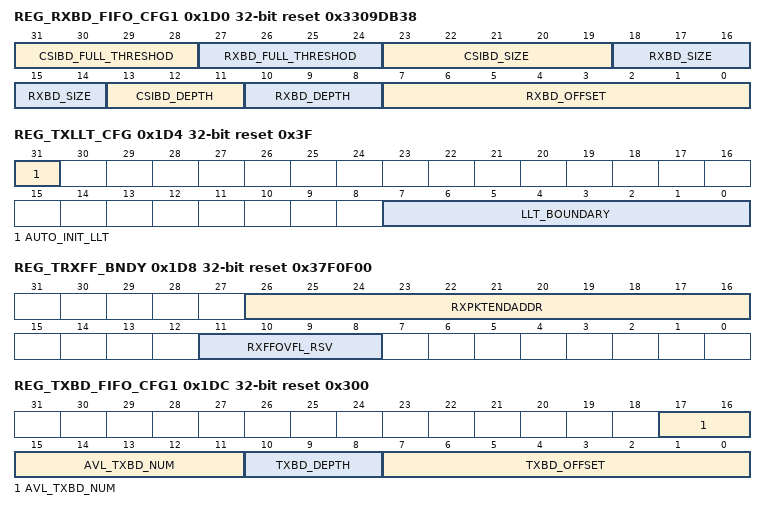
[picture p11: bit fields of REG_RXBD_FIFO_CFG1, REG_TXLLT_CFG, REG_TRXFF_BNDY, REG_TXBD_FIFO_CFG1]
0x1D0 REG_RXBD_FIFO_CFG1 reset 0x3309DB38
  [31:28] CSIBD_FULL_THRESHOD — csibd fifo almost full threshold. Gen interrupt when available csibd numbers smaller than the reg
  [27:24] RXBD_FULL_THRESHOD — rxbd fifo almost full threshold. Gen interrupt when available rxbd numbers smaller than the reg
  [23:19] CSIBD_SIZE — one rxbd corresponding host memory size,unit 256byts
  [18:14] RXBD_SIZE — one rxbd corresponding host memory size,unit 256byts
  [13:11] CSIBD_DEPTH — 2^N, N max is 6.default is 8
  [10:8] RXBD_DEPTH — 2^N, N max is 6.default is 8
  [7:0] RXBD_OFFSET — start address of RXBD FIFO
0x1D4 REG_TXLLT_CFG reset 0x3F
  [31] AUTO_INIT_LLT
  [7:0] LLT_BOUNDARY — boundary of LLT and the limit size of LLT. The default is 64.
0x1D8 REG_TRXFF_BNDY reset 0x37F0F00 — FIFO Boundary control register
  [26:16] RXPKTENDADDR — This register sets the upper boundary of RXFF0. The unit is 8 byte. The available memory space in RXPKTBUF for RXFF0 is configurable.
  [11:8] RXFFOVFL_RSV — Use this register to set reserved entries number of rxpktbuffer for overflow judgment. The rxpktbuffer overflow will be pre-asserted if the left entries count meets the value set here.
0x1DC REG_TXBD_FIFO_CFG1 access per field reset 0x300
  [17:11] AVL_TXBD_NUM ro — available txbd num in txbd fifo
  [10:8] TXBD_DEPTH rw — 2^N, N max is 6.default is 8
  [7:0] TXBD_OFFSET rw — start address of TXBD FIFO
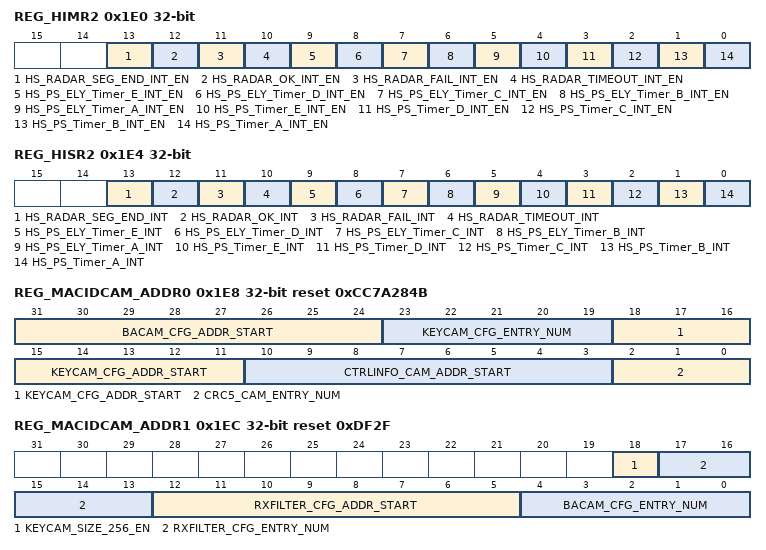
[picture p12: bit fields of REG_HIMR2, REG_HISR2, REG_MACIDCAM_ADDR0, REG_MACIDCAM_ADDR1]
0x1E0 REG_HIMR2
  [13] HS_RADAR_SEG_END_INT_EN, [12] HS_RADAR_OK_INT_EN, [11] HS_RADAR_FAIL_INT_EN, [10] HS_RADAR_TIMEOUT_INT_EN, [9] HS_PS_ELY_Timer_E_INT_EN, [8] HS_PS_ELY_Timer_D_INT_EN, [7] HS_PS_ELY_Timer_C_INT_EN, [6] HS_PS_ELY_Timer_B_INT_EN, [5] HS_PS_ELY_Timer_A_INT_EN, [4] HS_PS_Timer_E_INT_EN, [3] HS_PS_Timer_D_INT_EN, [2] HS_PS_Timer_C_INT_EN, [1] HS_PS_Timer_B_INT_EN, [0] HS_PS_Timer_A_INT_EN
0x1E4 REG_HISR2 ro
  [13] HS_RADAR_SEG_END_INT, [12] HS_RADAR_OK_INT, [11] HS_RADAR_FAIL_INT, [10] HS_RADAR_TIMEOUT_INT, [9] HS_PS_ELY_Timer_E_INT, [8] HS_PS_ELY_Timer_D_INT, [7] HS_PS_ELY_Timer_C_INT, [6] HS_PS_ELY_Timer_B_INT, [5] HS_PS_ELY_Timer_A_INT, [4] HS_PS_Timer_E_INT, [3] HS_PS_Timer_D_INT, [2] HS_PS_Timer_C_INT, [1] HS_PS_Timer_B_INT, [0] HS_PS_Timer_A_INT
0x1E8 REG_MACIDCAM_ADDR0 reset 0xCC7A284B
  [31:24] BACAM_CFG_ADDR_START — Start address of bacam for ba cfg, which should be 0x1b8[18:11] + 0x1b8[23:19] + 4*2*0x1b8[23:19]
  [23:19] KEYCAM_CFG_ENTRY_NUM — Total entry numbers for key cfg cam, 1 entry=8byte=2 key cfg
  [18:11] KEYCAM_CFG_ADDR_START — Start address of keycam for key cfg, which should be 10*2*0x1b8[2:0] + 0x1b8[10:3]
  [10:3] CTRLINFO_CAM_ADDR_START — Start address of ctrl info cam, which should be 3*0x1b8[2:0]
  [2:0] CRC5_CAM_ENTRY_NUM — Crc5 entry number for either A1,A2 and A3, 1 entry =8byte=10 crc5 should greater than 0, default is 3,which means the max macid number is 30.
0x1EC REG_MACIDCAM_ADDR1 reset 0xDF2F
  [18] KEYCAM_SIZE_256_EN — 1: key size in keycam is 256bit 0: key size in keycam depend on ex_sectype in keycam cfg
  [17:13] RXFILTER_CFG_ENTRY_NUM — Total entry numbers for rx filter cfg cam, 1 entry=8byte=2 rx filter cfg
  [12:5] RXFILTER_CFG_ADDR_START — Start address of rxfilter cam, which should be 0x1b8[31:24] + 0x1bc[4:0] + 2*0x1bc[4:0]
  [4:0] BACAM_CFG_ENTRY_NUM — Total entry numbers for rxba cfg cam,1 entry=8byte=2 BA cfg
0x1F0 REG_DUMMY_PAGE1_ON
  [7:0] DUMMY
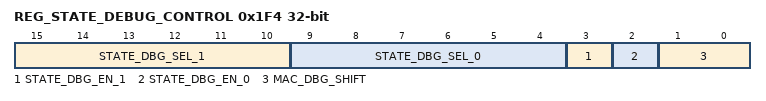
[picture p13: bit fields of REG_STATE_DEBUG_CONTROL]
0x1F4 REG_STATE_DEBUG_CONTROL
  [15:10] STATE_DBG_SEL_1 — select state machine 1 for debug port
  [9:4] STATE_DBG_SEL_0 — select state machine 0 for debug port
  [3] STATE_DBG_EN_1 — enable state machine 1 for debug port
  [2] STATE_DBG_EN_0 — enable state machine 1 for debug port
  [1:0] MAC_DBG_SHIFT — MACDEBUG[31:0] byte shift control signal 2'b00: MACDEBUG[31:0] 2'b01:{MACDEBUG[7:0],MACDEBUG[31:8]} 2'b10:{MACDEBUG[15:0],MACDEBUG[31:16]} 2'b11:{MACDEBUG[23:0],MACDEBUG[31:24]}
